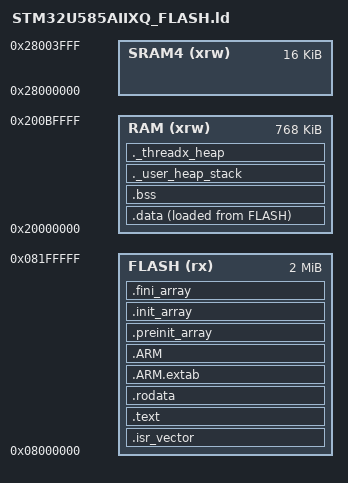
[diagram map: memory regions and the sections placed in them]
/*
******************************************************************************
**
**  File        : LinkerScript.ld
**
**  Author      : STM32CubeIDE
**
**  Abstract    : Linker script for STM32U585xI Device from STM32U5 series
**                      2048Kbytes FLASH
**                      784Kbytes RAM
**
**                Set heap size, stack size and stack location according
**                to application requirements.
**
**                Set memory bank area and size if external memory is used.
**
**  Target      : STMicroelectronics STM32
**
**  Distribution: The file is distributed as is without any warranty
**                of any kind.
**
*****************************************************************************
** @attention
**
** Copyright (c) 2021 STMicroelectronics.
** All rights reserved.
**
** This software is licensed under terms that can be found in the LICENSE file
** in the root directory of this software component.
** If no LICENSE file comes with this software, it is provided AS-IS.
**
*****************************************************************************
*/

/* Entry Point */
ENTRY(Reset_Handler)

/* Highest address of the user mode stack */
_estack = ORIGIN(RAM) + LENGTH(RAM);	/* end of "RAM" Ram type memory */

_Min_Heap_Size = 0x20000 ;	/* required amount of heap  */
_Min_Stack_Size = 0x1000 ;	/* required amount of stack */

/* Memories definition */
MEMORY
{
  RAM	(xrw)	: ORIGIN = 0x20000000,	LENGTH = 768K
  SRAM4	(xrw)	: ORIGIN = 0x28000000,	LENGTH = 16K
  FLASH	(rx)	: ORIGIN = 0x08000000,	LENGTH = 2048K
}

/* Sections */
SECTIONS
{
  /* The startup code into "FLASH" Rom type memory */
  .isr_vector :
  {
    KEEP(*(.isr_vector)) /* Startup code */
  } >FLASH

  /* The program code and other data into "FLASH" Rom type memory */
  .text :
  {
    *(.text)           /* .text sections (code) */
    *(.text*)          /* .text* sections (code) */
    *(.glue_7)         /* glue arm to thumb code */
    *(.glue_7t)        /* glue thumb to arm code */
    *(.eh_frame)

    KEEP (*(.init))
    KEEP (*(.fini))
    . = ALIGN (4) ;
    /* AliOS Things cli start */
    _cli_region_begin = .;
    KEEP(*(CliRegion))
    . = ALIGN(4);
    _cli_region_end = .;
    /* AliOS Things cli end */

    /* AliOS Things driver subsystem start*/
    __core_driver_start__ = .;
    KEEP(*(.core_driver_entry))
    . = ALIGN(4);
    __core_driver_end__ = .;

    __bus_driver_start__ = .;
    KEEP(*(*.bus_driver_entry))
    __bus_driver_end__ = .;

    __early_driver_start__ = .;
    KEEP(*(*.early_driver_entry))
    __early_driver_end__ = .;

    __vfs_driver_start__ = .;
    KEEP(*(*.vfs_driver_entry))
    __vfs_driver_end__ = .;

    __level0_driver_start__ = .;
    KEEP(*(*.level0_driver_entry))
    __level0_driver_end__ = .;

    __level1_driver_start__ = .;
    KEEP(*(*.level1_driver_entry))
    __level1_driver_end__ = .;

    __level2_driver_start__ = .;
    KEEP(*(*.level2_driver_entry))
    __level2_driver_end__ = .;

    __level3_driver_start__ = .;
    KEEP(*(*.level3_driver_entry))
    __level3_driver_end__ = .;

    __post_driver_start__ = .;
    KEEP(*(*.post_driver_entry))
    __post_driver_end__ = .;
    /* AliOS Things driver subsystem end. */

    /* For C++ support start */
    . = ALIGN(0x4) ;
    PROVIDE_HIDDEN (__preinit_array_start = .);
    KEEP(*(.preinit_array))
    PROVIDE_HIDDEN (__preinit_array_end = .);

    . = ALIGN(4);
    PROVIDE(__ctors_start__ = .);
    PROVIDE_HIDDEN (__init_array_start = .);
    KEEP(*(SORT(.init_array.*)))
    KEEP(*(.init_array))
    PROVIDE_HIDDEN (__init_array_end = .);
    PROVIDE(__ctors_end__ = .);

    . = ALIGN(4);
    PROVIDE(__dtors_start__ = .);
    PROVIDE_HIDDEN (__fini_array_start = .);
    KEEP(*(SORT(.fini_array.*)))
    KEEP(*(.fini_array))
    PROVIDE_HIDDEN (__fini_array_end = .);
    PROVIDE(__dtors_end__ = .);
    /* For C++ support end */

    _etext = .;        /* define a global symbols at end of code */
  } >FLASH

  /* Constant data into "FLASH" Rom type memory */
  .rodata :
  {
    *(.rodata)         /* .rodata sections (constants, strings, etc.) */
    *(.rodata*)        /* .rodata* sections (constants, strings, etc.) */
  } >FLASH

  .ARM.extab :
  {
    *(.ARM.extab* .gnu.linkonce.armextab.*)
  } >FLASH

  .ARM :
  {
    __exidx_start = .;
    *(.ARM.exidx*)
    __exidx_end = .;
  } >FLASH

  .preinit_array :
  {
    PROVIDE_HIDDEN (__preinit_array_start = .);
    KEEP (*(.preinit_array*))
    PROVIDE_HIDDEN (__preinit_array_end = .);
  } >FLASH

  .init_array :
  {
    PROVIDE_HIDDEN (__init_array_start = .);
    KEEP (*(SORT(.init_array.*)))
    KEEP (*(.init_array*))
    PROVIDE_HIDDEN (__init_array_end = .);
  } >FLASH

  .fini_array :
  {
    PROVIDE_HIDDEN (__fini_array_start = .);
    KEEP (*(SORT(.fini_array.*)))
    KEEP (*(.fini_array*))
    PROVIDE_HIDDEN (__fini_array_end = .);
  } >FLASH

  /* Used by the startup to initialize data */
  _sidata = LOADADDR(.data);

  /* Initialized data sections into "RAM" Ram type memory */
  .data :
  {
    _sdata = .;        /* create a global symbol at data start */
    *(.data)           /* .data sections */
    *(.data*)          /* .data* sections */
    *(.RamFunc)        /* .RamFunc sections */
    *(.RamFunc*)       /* .RamFunc* sections */

    _edata = .;        /* define a global symbol at data end */
  } >RAM AT> FLASH

  /* Uninitialized data section into "RAM" Ram type memory */
  .bss :
  {
    /* This is used by the startup in order to initialize the .bss section */
    _sbss = .;         /* define a global symbol at bss start */
    __bss_start__ = _sbss;
    *(.bss)
    *(.bss*)
    *(COMMON)

    _ebss = .;         /* define a global symbol at bss end */
    __bss_end__ = _ebss;
  } >RAM

  /* User_heap_stack section, used to check that there is enough "RAM" Ram type memory left */
  ._user_heap_stack :
  {
    . = ALIGN(8);
    PROVIDE ( end = . );
    PROVIDE ( _end = . );
    . = . + _Min_Heap_Size;
    . = . + _Min_Stack_Size;
    . = ALIGN(8);
  } >RAM
  
  ._threadx_heap :
  {
    . = ALIGN(8);
    __RAM_segment_used_end__ = .;
    . = . + 64K;
    . = ALIGN(8);
   } >RAM AT> RAM

  /* Remove information from the compiler libraries */
  /DISCARD/ :
  {
    libc.a ( * )
    libm.a ( * )
    libgcc.a ( * )
  }

  .ARM.attributes 0 : { *(.ARM.attributes) }
}
